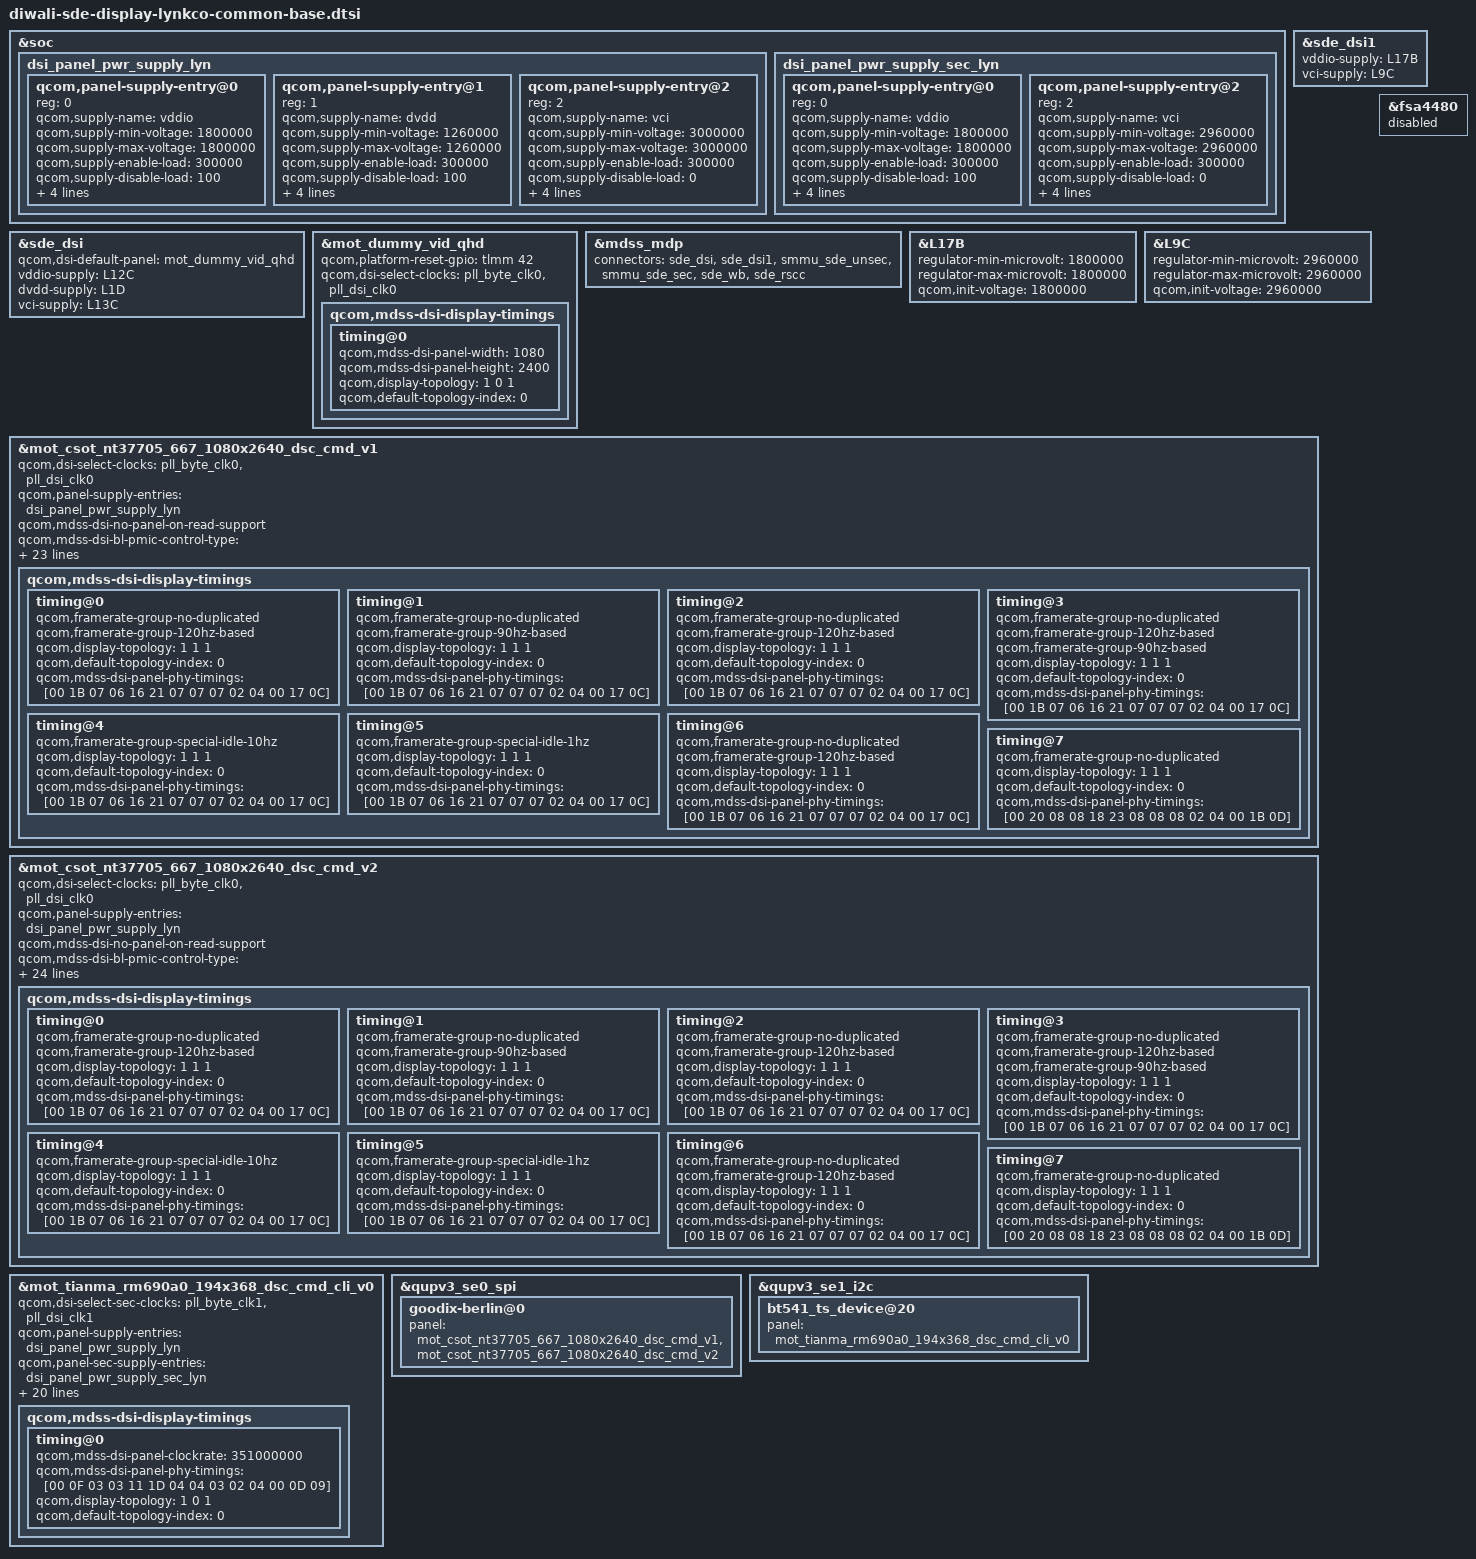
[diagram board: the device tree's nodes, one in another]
/*
   This base is original from "diwali-sde-display-qrd.dtsi"
*/
#include "diwali-sde-display.dtsi"
#include "dsi-panel-mot-dummy-qhd-video.dtsi"
#include "dsi-panel-mot-tianma-rm690a0-194x368-dsc-cmd-common-cli_v0.dtsi"
#include "dsi-panel-mot-csot-nt37705-667-1080x2640-dsc-cmd-common_ly_v1.dtsi"
#include "dsi-panel-mot-csot-nt37705-667-1080x2640-dsc-cmd-common_ly_v2.dtsi"

&soc {
	dsi_panel_pwr_supply_lyn: dsi_panel_pwr_supply_lyn {
		#address-cells = <1>;
		#size-cells = <0>;

	qcom,panel-supply-entry@0 {
		reg = <0>;
		qcom,supply-name = "vddio";
		qcom,supply-min-voltage = <1800000>;
		qcom,supply-max-voltage = <1800000>;
		qcom,supply-enable-load = <300000>;
		qcom,supply-disable-load = <100>;
		qcom,supply-pre-on-sleep = <1>;
		qcom,supply-post-on-sleep = <1>;
		qcom,supply-pre-off-sleep = <3>;
		qcom,supply-post-off-sleep = <0>;
        };
	qcom,panel-supply-entry@1 {
		reg = <1>;
		qcom,supply-name = "dvdd";
		qcom,supply-min-voltage = <1260000>;
		qcom,supply-max-voltage = <1260000>;
		qcom,supply-enable-load = <300000>;
		qcom,supply-disable-load = <100>;
		qcom,supply-pre-on-sleep = <1>;
		qcom,supply-post-on-sleep = <1>;
		qcom,supply-pre-off-sleep = <3>;
		qcom,supply-post-off-sleep = <0>;
        };

        qcom,panel-supply-entry@2 {
		reg = <2>;
		qcom,supply-name = "vci";
		qcom,supply-min-voltage = <3000000>;
		qcom,supply-max-voltage = <3000000>;
		qcom,supply-enable-load = <300000>;
		qcom,supply-disable-load = <0>;
		qcom,supply-pre-on-sleep = <1>;
		qcom,supply-post-on-sleep = <0>;
		qcom,supply-pre-off-sleep = <2>;
		qcom,supply-post-off-sleep = <0>;
        };
	};

	dsi_panel_pwr_supply_sec_lyn: dsi_panel_pwr_supply_sec_lyn {
		#address-cells = <1>;
		#size-cells = <0>;

	qcom,panel-supply-entry@0 {
		reg = <0>;
		qcom,supply-name = "vddio";
		qcom,supply-min-voltage = <1800000>;
		qcom,supply-max-voltage = <1800000>;
		qcom,supply-enable-load = <300000>;
		qcom,supply-disable-load = <100>;
		qcom,supply-pre-on-sleep = <1>;
		qcom,supply-post-on-sleep = <1>;
		qcom,supply-pre-off-sleep = <11>;
		qcom,supply-post-off-sleep = <0>;
        };

        qcom,panel-supply-entry@2 {
		reg = <2>;
		qcom,supply-name = "vci";
		qcom,supply-min-voltage = <2960000>;
		qcom,supply-max-voltage = <2960000>;
		qcom,supply-enable-load = <300000>;
		qcom,supply-disable-load = <0>;
		qcom,supply-pre-on-sleep = <1>;
		qcom,supply-post-on-sleep = <0>;
		qcom,supply-pre-off-sleep = <2>;
		qcom,supply-post-off-sleep = <0>;
        };
	};

};
&sde_dsi {
	qcom,dsi-default-panel = <&mot_dummy_vid_qhd>;
};
&mot_dummy_vid_qhd {
       qcom,mdss-dsi-display-timings {
                timing@0{
                       qcom,mdss-dsi-panel-width = <1080>;
                       qcom,mdss-dsi-panel-height = <2400>;
               };
       };
};

&sde_dsi {
	vddio-supply = <&L12C>;
	dvdd-supply = <&L1D>;
	vci-supply = <&L13C>;
};

&sde_dsi1 {
	vddio-supply = <&L17B>;
	vci-supply = <&L9C>;
};

&mdss_mdp {
	connectors = <&sde_dsi &sde_dsi1 &smmu_sde_unsec &smmu_sde_sec &sde_wb &sde_rscc>;
};

//sec display 1.8 vddio
&L17B {
	regulator-min-microvolt = <1800000>;
	regulator-max-microvolt = <1800000>;
	qcom,init-voltage = <1800000>;
};
//sec display 2.96 vci
&L9C {
	regulator-min-microvolt = <2960000>;
	regulator-max-microvolt = <2960000>;
	qcom,init-voltage = <2960000>;
};


&mot_csot_nt37705_667_1080x2640_dsc_cmd_v1 {
	qcom,dsi-select-clocks = "pll_byte_clk0", "pll_dsi_clk0";
	qcom,panel-supply-entries = <&dsi_panel_pwr_supply_lyn>;
	qcom,mdss-dsi-no-panel-on-read-support;
	qcom,mdss-dsi-bl-pmic-control-type = "bl_ctrl_dcs";
	qcom,mdss-dsi-bl-min-level = <420>;
	qcom,mdss-dsi-bl-max-level = <16380>;
	qcom,mdss-dsi-bl-default-level = <10230>;
	qcom,mdss-brightness-max-level = <16380>;
	qcom,platform-reset-gpio = <&tlmm 42 0>;
	qcom,bl-dsc-cmd-state = "dsi_hs_mode";
	qcom,mdss-dsi-bl-inverted-dbv;
	qcom,mdss-dsi-bl-is-exponent;


	qcom,mdss-dsi-panel-status-check-mode = "reg_read";
	qcom,mdss-dsi-panel-status-command = [06 01 00 01 00 00 01 0a];
	qcom,mdss-dsi-panel-status-command-state = "dsi_lp_mode";
	qcom,mdss-dsi-panel-status-value = <0x9c>;
	qcom,mdss-dsi-panel-status-read-length = <1>;
	qcom,esd-check-enabled;
	qcom,cellid-read-enabled;
	qcom,mdss-dsi-panel-cellid-read-length = <36>;
	qcom,mdss-dsi-panel-cellid-offset = <13>;
	qcom,mdss-dsi-panel-cellid-command = [
		06 01 00 01 00 00 01 AC];
	qcom,mdss-dsi-display-timings {
		timing@0 { //120
			qcom,framerate-group-no-duplicated;
			qcom,framerate-group-120hz-based;
			//qcom,mdss-dsi-panel-clockrate = <880000000>;
			qcom,display-topology = <1 1 1>;
			qcom,default-topology-index = <0>;
			qcom,mdss-dsi-panel-phy-timings = [00 1B 07 06 16 21 07
							07 07 02 04 00 17 0C];
		};
		timing@1 { //90
			qcom,framerate-group-no-duplicated;
			qcom,framerate-group-90hz-based;
			//qcom,mdss-dsi-panel-clockrate = <880000000>;
			qcom,display-topology = <1 1 1>;
			qcom,default-topology-index = <0>;
			qcom,mdss-dsi-panel-phy-timings = [00 1B 07 06 16 21 07
							07 07 02 04 00 17 0C];
		};
		timing@2 { //60
			qcom,framerate-group-no-duplicated;
			qcom,framerate-group-120hz-based;
			//qcom,mdss-dsi-panel-clockrate = <880000000>;
			qcom,display-topology = <1 1 1>;
			qcom,default-topology-index = <0>;
			qcom,mdss-dsi-panel-phy-timings = [00 1B 07 06 16 21 07
							07 07 02 04 00 17 0C];
		};
		timing@3 { //30
			qcom,framerate-group-no-duplicated;
			qcom,framerate-group-120hz-based;
			qcom,framerate-group-90hz-based;
			//qcom,mdss-dsi-panel-clockrate = <880000000>;
			qcom,display-topology = <1 1 1>;
			qcom,default-topology-index = <0>;
			qcom,mdss-dsi-panel-phy-timings = [00 1B 07 06 16 21 07
							07 07 02 04 00 17 0C];
		};
		timing@4 { //10 independent
			qcom,framerate-group-special-idle-10hz;
			//qcom,mdss-dsi-panel-clockrate = <880000000>;
			qcom,display-topology = <1 1 1>;
			qcom,default-topology-index = <0>;
			qcom,mdss-dsi-panel-phy-timings = [00 1B 07 06 16 21 07
							07 07 02 04 00 17 0C];
		};
		timing@5 { //1 independent
			qcom,framerate-group-special-idle-1hz;
			//qcom,mdss-dsi-panel-clockrate = <880000000>;
			qcom,display-topology = <1 1 1>;
			qcom,default-topology-index = <0>;
			qcom,mdss-dsi-panel-phy-timings = [00 1B 07 06 16 21 07
							07 07 02 04 00 17 0C];
		};
		timing@6 { //24
			qcom,framerate-group-no-duplicated;
			qcom,framerate-group-120hz-based;
			//qcom,mdss-dsi-panel-clockrate = <880000000>;
			qcom,display-topology = <1 1 1>;
			qcom,default-topology-index = <0>;
			qcom,mdss-dsi-panel-phy-timings = [00 1B 07 06 16 21 07
							07 07 02 04 00 17 0C];
		};
		timing@7 { //144
			qcom,framerate-group-no-duplicated;
			//qcom,mdss-dsi-panel-clockrate = <880000000>;
			qcom,display-topology = <1 1 1>;
			qcom,default-topology-index = <0>;
			qcom,mdss-dsi-panel-phy-timings = [00 20 08 08 18 23 08
							08 08 02 04 00 1B 0D];
		};
	};
};

&mot_csot_nt37705_667_1080x2640_dsc_cmd_v2 {
	qcom,dsi-select-clocks = "pll_byte_clk0", "pll_dsi_clk0";
	qcom,panel-supply-entries = <&dsi_panel_pwr_supply_lyn>;
	qcom,mdss-dsi-no-panel-on-read-support;
	qcom,mdss-dsi-bl-pmic-control-type = "bl_ctrl_dcs";
	qcom,mdss-dsi-bl-min-level = <420>;
	qcom,mdss-dsi-bl-max-level = <16380>;
	qcom,mdss-dsi-bl-default-level = <10230>;
	qcom,mdss-brightness-max-level = <16380>;
	qcom,platform-reset-gpio = <&tlmm 42 0>;
	qcom,bl-dsc-cmd-state = "dsi_hs_mode";
	qcom,mdss-dsi-bl-inverted-dbv;
	qcom,mdss-dsi-bl-is-exponent;
	qcom,mdss-dsi-panel-declare = "1:1";

	qcom,mdss-dsi-panel-status-check-mode = "reg_read";
	qcom,mdss-dsi-panel-status-command = [06 01 00 01 00 00 01 0a];
	qcom,mdss-dsi-panel-status-command-state = "dsi_lp_mode";
	qcom,mdss-dsi-panel-status-value = <0x9c>;
	qcom,mdss-dsi-panel-status-read-length = <1>;
	qcom,esd-check-enabled;
	qcom,cellid-read-enabled;
	qcom,mdss-dsi-panel-cellid-read-length = <36>;
	qcom,mdss-dsi-panel-cellid-offset = <13>;
	qcom,mdss-dsi-panel-cellid-command = [
		06 01 00 01 00 00 01 AC];
	qcom,mdss-dsi-display-timings {
		timing@0 { //120
			qcom,framerate-group-no-duplicated;
			qcom,framerate-group-120hz-based;
			//qcom,mdss-dsi-panel-clockrate = <880000000>;
			qcom,display-topology = <1 1 1>;
			qcom,default-topology-index = <0>;
			qcom,mdss-dsi-panel-phy-timings = [00 1B 07 06 16 21 07
							07 07 02 04 00 17 0C];
		};
		timing@1 { //90
			qcom,framerate-group-no-duplicated;
			qcom,framerate-group-90hz-based;
			//qcom,mdss-dsi-panel-clockrate = <880000000>;
			qcom,display-topology = <1 1 1>;
			qcom,default-topology-index = <0>;
			qcom,mdss-dsi-panel-phy-timings = [00 1B 07 06 16 21 07
							07 07 02 04 00 17 0C];
		};
		timing@2 { //60
			qcom,framerate-group-no-duplicated;
			qcom,framerate-group-120hz-based;
			//qcom,mdss-dsi-panel-clockrate = <880000000>;
			qcom,display-topology = <1 1 1>;
			qcom,default-topology-index = <0>;
			qcom,mdss-dsi-panel-phy-timings = [00 1B 07 06 16 21 07
							07 07 02 04 00 17 0C];
		};
		timing@3 { //30
			qcom,framerate-group-no-duplicated;
			qcom,framerate-group-120hz-based;
			qcom,framerate-group-90hz-based;
			//qcom,mdss-dsi-panel-clockrate = <880000000>;
			qcom,display-topology = <1 1 1>;
			qcom,default-topology-index = <0>;
			qcom,mdss-dsi-panel-phy-timings = [00 1B 07 06 16 21 07
							07 07 02 04 00 17 0C];
		};
		timing@4 { //10 independent
			qcom,framerate-group-special-idle-10hz;
			//qcom,mdss-dsi-panel-clockrate = <880000000>;
			qcom,display-topology = <1 1 1>;
			qcom,default-topology-index = <0>;
			qcom,mdss-dsi-panel-phy-timings = [00 1B 07 06 16 21 07
							07 07 02 04 00 17 0C];
		};
		timing@5 { //1 independent
			qcom,framerate-group-special-idle-1hz;
			//qcom,mdss-dsi-panel-clockrate = <880000000>;
			qcom,display-topology = <1 1 1>;
			qcom,default-topology-index = <0>;
			qcom,mdss-dsi-panel-phy-timings = [00 1B 07 06 16 21 07
							07 07 02 04 00 17 0C];
		};
		timing@6 { //24
			qcom,framerate-group-no-duplicated;
			qcom,framerate-group-120hz-based;
			//qcom,mdss-dsi-panel-clockrate = <880000000>;
			qcom,display-topology = <1 1 1>;
			qcom,default-topology-index = <0>;
			qcom,mdss-dsi-panel-phy-timings = [00 1B 07 06 16 21 07
							07 07 02 04 00 17 0C];
		};
		timing@7 { //144
			qcom,framerate-group-no-duplicated;
			//qcom,mdss-dsi-panel-clockrate = <880000000>;
			qcom,display-topology = <1 1 1>;
			qcom,default-topology-index = <0>;
			qcom,mdss-dsi-panel-phy-timings = [00 20 08 08 18 23 08
							08 08 02 04 00 1B 0D];
		};
	};
};

&mot_tianma_rm690a0_194x368_dsc_cmd_cli_v0 {
	qcom,dsi-select-sec-clocks = "pll_byte_clk1", "pll_dsi_clk1";

	qcom,panel-supply-entries = <&dsi_panel_pwr_supply_lyn>;
	qcom,panel-sec-supply-entries = <&dsi_panel_pwr_supply_sec_lyn>;
	qcom,mdss-dsi-bl-pmic-control-type = "bl_ctrl_dcs";
	qcom,mdss-dsi-sec-bl-pmic-control-type = "bl_ctrl_dcs";
	qcom,mdss-dsi-bl-min-level = <3>;
	qcom,mdss-dsi-bl-max-level = <325>;
	qcom,mdss-dsi-bl-default-level = <195>;
	qcom,mdss-brightness-max-level = <325>;
	qcom,platform-sec-vci-enable-gpio = <&tlmm 46 0>;
	qcom,platform-sec-reset-gpio = <&tlmm 6 0>;
	qcom,mdss-dsi-panel-status-check-mode = "reg_read";
	qcom,mdss-dsi-panel-status-command = [06 01 00 01 00 00 01 0a];
	qcom,mdss-dsi-panel-status-command-state = "dsi_lp_mode";
	qcom,mdss-dsi-panel-status-value = <0xb4>;
	qcom,mdss-dsi-panel-status-read-length = <1>;
	qcom,esd-check-enabled;

	qcom,mdss-dsi-no-panel-on-read-support;

	qcom,mdss-dsi-display-timings {
		timing@0{
			qcom,mdss-dsi-panel-clockrate = <351000000>;
			qcom,mdss-dsi-panel-phy-timings = [00 0F 03 03 11 1D 04
				04 03 02 04 00 0D 09];
			qcom,display-topology = <1 0 1>;
			qcom,default-topology-index = <0>;
		};
	};
};

&mot_dummy_vid_qhd {
	qcom,platform-reset-gpio = <&tlmm 42 0>;

	qcom,dsi-select-clocks = "pll_byte_clk0", "pll_dsi_clk0";
	qcom,mdss-dsi-display-timings {
		timing@0 {
			qcom,display-topology = <1 0 1>;
			qcom,default-topology-index = <0>;
		};
	};
};

&fsa4480 {
	status = "disabled";
};

&qupv3_se0_spi {
	goodix-berlin@0 {
		panel = <&mot_csot_nt37705_667_1080x2640_dsc_cmd_v1
			 &mot_csot_nt37705_667_1080x2640_dsc_cmd_v2>;
	};
};

&qupv3_se1_i2c {
	bt541_ts_device@20 {
		panel = <&mot_tianma_rm690a0_194x368_dsc_cmd_cli_v0>;
	};
};
